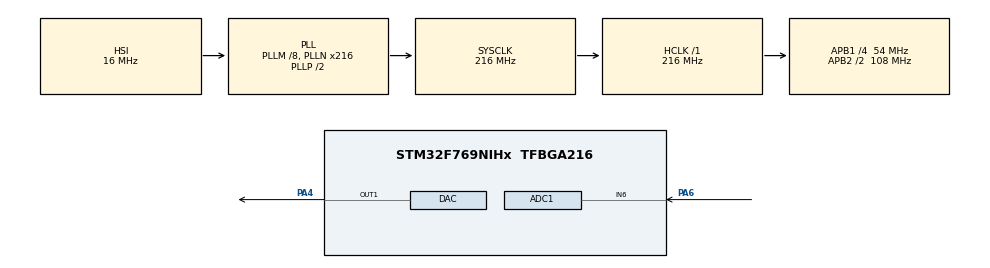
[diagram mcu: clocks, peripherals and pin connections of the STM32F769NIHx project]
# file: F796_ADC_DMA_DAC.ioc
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ADC1.Channel-3\#ChannelRegularConversion=ADC_CHANNEL_6
ADC1.ContinuousConvMode=DISABLE
ADC1.DMAContinuousRequests=ENABLE
ADC1.ExternalTrigConv=ADC_EXTERNALTRIGCONV_T6_TRGO
ADC1.InjNumberOfConversion=0
ADC1.NbrOfConversion=1
ADC1.NbrOfConversionFlag=1
ADC1.Rank-3\#ChannelRegularConversion=1
ADC1.Resolution=ADC_RESOLUTION_12B
ADC1.SamplingTime-3\#ChannelRegularConversion=ADC_SAMPLETIME_3CYCLES
ADC1.master=1
DAC.DAC_OutputBuffer=DAC_OUTPUTBUFFER_ENABLE
DAC.DAC_Trigger=DAC_TRIGGER_T6_TRGO
Dma.ADC1.1.Direction=DMA_PERIPH_TO_MEMORY
Dma.ADC1.1.FIFOMode=DMA_FIFOMODE_DISABLE
Dma.ADC1.1.Instance=DMA2_Stream0
Dma.ADC1.1.MemDataAlignment=DMA_MDATAALIGN_WORD
Dma.ADC1.1.MemInc=DMA_MINC_ENABLE
Dma.ADC1.1.Mode=DMA_CIRCULAR
Dma.ADC1.1.PeriphDataAlignment=DMA_PDATAALIGN_WORD
Dma.ADC1.1.PeriphInc=DMA_PINC_DISABLE
Dma.ADC1.1.Priority=DMA_PRIORITY_HIGH
Dma.DAC1.0.Direction=DMA_MEMORY_TO_PERIPH
Dma.DAC1.0.FIFOMode=DMA_FIFOMODE_DISABLE
Dma.DAC1.0.Instance=DMA1_Stream5
Dma.DAC1.0.MemDataAlignment=DMA_MDATAALIGN_WORD
Dma.DAC1.0.MemInc=DMA_MINC_ENABLE
Dma.DAC1.0.Mode=DMA_CIRCULAR
Dma.DAC1.0.PeriphDataAlignment=DMA_PDATAALIGN_WORD
Dma.DAC1.0.PeriphInc=DMA_PINC_DISABLE
Dma.DAC1.0.Priority=DMA_PRIORITY_HIGH
Dma.Request0=DAC1
Dma.Request1=ADC1
Mcu.Family=STM32F7
Mcu.Name=STM32F769NIHx
Mcu.Package=TFBGA216
NVIC.DMA1_Stream5_IRQn=true\:0\:0\:false\:false\:true\:false\:true
NVIC.DMA2_Stream0_IRQn=true\:0\:0\:false\:false\:true\:false\:true
NVIC.PriorityGroup=NVIC_PRIORITYGROUP_4
PA13.Mode=Serial_Wire
PA13.Signal=SYS_JTMS-SWDIO
PA14.Mode=Serial_Wire
PA14.Signal=SYS_JTCK-SWCLK
PA4.Signal=COMP_DAC1_group
PA6.Signal=ADCx_IN6
ProjectManager.HeapSize=0x200
ProjectManager.StackSize=0x400
ProjectManager.TargetToolchain=STM32CubeIDE
RCC.AHBFreq_Value=216000000
RCC.APB1CLKDivider=RCC_HCLK_DIV4
RCC.APB1Freq_Value=54000000
RCC.APB1TimFreq_Value=108000000
RCC.APB2CLKDivider=RCC_HCLK_DIV2
RCC.APB2Freq_Value=108000000
RCC.APB2TimFreq_Value=216000000
RCC.CortexFreq_Value=216000000
RCC.HCLKFreq_Value=216000000
RCC.HSE_VALUE=25000000
RCC.HSI_VALUE=16000000
RCC.LSE_VALUE=32768
RCC.PLLM=8
RCC.PLLN=216
RCC.PLLQ=4
RCC.PLLSAIQ=3
RCC.SYSCLKFreq_VALUE=216000000
RCC.SYSCLKSource=RCC_SYSCLKSOURCE_PLLCLK
RCC.USBFreq_Value=108000000
RCC.VCOOutputFreq_Value=432000000
SH.ADCx_IN6.0=ADC1_IN6,IN6
SH.COMP_DAC1_group.0=DAC_OUT1,DAC_OUT1
TIM6.Period=120
TIM6.TIM_MasterOutputTrigger=TIM_TRGO_UPDATE
VP_TIM6_VS_ClockSourceINT.Mode=Enable_Timer
board=STM32F769I-DISCO

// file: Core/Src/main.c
/* USER CODE BEGIN Header */
/**
  ******************************************************************************
  * @file           : main.c
  * @brief          : Main program body
  ******************************************************************************
  * @attention
  *
  * <h2><center>&copy; Copyright (c) 2021 STMicroelectronics.
  * All rights reserved.</center></h2>
  *
  * This software component is licensed by ST under BSD 3-Clause license,
  * the "License"; You may not use this file except in compliance with the
  * License. You may obtain a copy of the License at:
  *                        opensource.org/licenses/BSD-3-Clause
  *
  ******************************************************************************
  */
/* USER CODE END Header */

#include "main.h"

ADC_HandleTypeDef hadc1;
DMA_HandleTypeDef hdma_adc1;

DAC_HandleTypeDef hdac;
DMA_HandleTypeDef hdma_dac1;

TIM_HandleTypeDef htim6;

/* USER CODE BEGIN PV */
// adc and dac buffer

// number of samples user accesses per data block
#define DATASIZE 128

//  full buffer size
#define FULLBUFFERSIZE 256

uint32_t adc_val[FULLBUFFERSIZE];
uint32_t dac_val[FULLBUFFERSIZE];

// pointers to th half-buffers which should be processed
static volatile uint32_t* inbufPtr;
static volatile uint32_t* outbufPtr;

void processDSP();
/* USER CODE END PV */

void SystemClock_Config(void);
static void MX_GPIO_Init(void);
static void MX_DMA_Init(void);
static void MX_ADC1_Init(void);
static void MX_DAC_Init(void);
static void MX_TIM6_Init(void);

int main(void)
{

  /* MCU Configuration--------------------------------------------------------*/

  /* Reset of all peripherals, Initializes the Flash interface and the Systick. */
  HAL_Init();

  /* Configure the system clock */
  SystemClock_Config();

  /* Initialize all configured peripherals */
  MX_GPIO_Init();
  MX_DMA_Init();
  MX_ADC1_Init();
  MX_DAC_Init();
  MX_TIM6_Init();
  /* USER CODE BEGIN 2 */
  for( int i = 0; i < FULLBUFFERSIZE; i++) {
  	dac_val[i] = i * 12;
  }

  HAL_TIM_Base_Start(&htim6);
  HAL_ADC_Start_DMA(&hadc1, (uint32_t*) adc_val, FULLBUFFERSIZE);
  HAL_DAC_Start_DMA(&hdac, DAC_CHANNEL_1, (uint32_t*) adc_val, FULLBUFFERSIZE, DAC_ALIGN_12B_R);
  /* USER CODE END 2 */

  /* Infinite loop */
  while (1)
  {

    /* USER CODE BEGIN 3 */
	//processDSP();
  }
  /* USER CODE END 3 */
}

void SystemClock_Config(void)
{
  RCC_OscInitTypeDef RCC_OscInitStruct = {0};
  RCC_ClkInitTypeDef RCC_ClkInitStruct = {0};

  /** Configure the main internal regulator output voltage
  */
  __HAL_RCC_PWR_CLK_ENABLE();
  __HAL_PWR_VOLTAGESCALING_CONFIG(PWR_REGULATOR_VOLTAGE_SCALE1);
  /** Initializes the CPU, AHB and APB busses clocks
  */
  RCC_OscInitStruct.OscillatorType = RCC_OSCILLATORTYPE_HSI;
  RCC_OscInitStruct.HSIState = RCC_HSI_ON;
  RCC_OscInitStruct.HSICalibrationValue = RCC_HSICALIBRATION_DEFAULT;
  RCC_OscInitStruct.PLL.PLLState = RCC_PLL_ON;
  RCC_OscInitStruct.PLL.PLLSource = RCC_PLLSOURCE_HSI;
  RCC_OscInitStruct.PLL.PLLM = 8;
  RCC_OscInitStruct.PLL.PLLN = 216;
  RCC_OscInitStruct.PLL.PLLP = RCC_PLLP_DIV2;
  RCC_OscInitStruct.PLL.PLLQ = 4;
  if (HAL_RCC_OscConfig(&RCC_OscInitStruct) != HAL_OK)
  {
    Error_Handler();
  }
  /** Activate the Over-Drive mode
  */
  if (HAL_PWREx_EnableOverDrive() != HAL_OK)
  {
    Error_Handler();
  }
  /** Initializes the CPU, AHB and APB busses clocks
  */
  RCC_ClkInitStruct.ClockType = RCC_CLOCKTYPE_HCLK|RCC_CLOCKTYPE_SYSCLK
                              |RCC_CLOCKTYPE_PCLK1|RCC_CLOCKTYPE_PCLK2;
  RCC_ClkInitStruct.SYSCLKSource = RCC_SYSCLKSOURCE_PLLCLK;
  RCC_ClkInitStruct.AHBCLKDivider = RCC_SYSCLK_DIV1;
  RCC_ClkInitStruct.APB1CLKDivider = RCC_HCLK_DIV4;
  RCC_ClkInitStruct.APB2CLKDivider = RCC_HCLK_DIV2;

  if (HAL_RCC_ClockConfig(&RCC_ClkInitStruct, FLASH_LATENCY_7) != HAL_OK)
  {
    Error_Handler();
  }
}

static void MX_ADC1_Init(void)
{

  ADC_ChannelConfTypeDef sConfig = {0};

  /** Configure the global features of the ADC (Clock, Resolution, Data Alignment and number of conversion)
  */
  hadc1.Instance = ADC1;
  hadc1.Init.ClockPrescaler = ADC_CLOCK_SYNC_PCLK_DIV4;
  hadc1.Init.Resolution = ADC_RESOLUTION_12B;
  hadc1.Init.ScanConvMode = ADC_SCAN_DISABLE;
  hadc1.Init.ContinuousConvMode = DISABLE;
  hadc1.Init.DiscontinuousConvMode = DISABLE;
  hadc1.Init.ExternalTrigConvEdge = ADC_EXTERNALTRIGCONVEDGE_RISING;
  hadc1.Init.ExternalTrigConv = ADC_EXTERNALTRIGCONV_T6_TRGO;
  hadc1.Init.DataAlign = ADC_DATAALIGN_RIGHT;
  hadc1.Init.NbrOfConversion = 1;
  hadc1.Init.DMAContinuousRequests = ENABLE;
  hadc1.Init.EOCSelection = ADC_EOC_SINGLE_CONV;
  if (HAL_ADC_Init(&hadc1) != HAL_OK)
  {
    Error_Handler();
  }
  /** Configure for the selected ADC regular channel its corresponding rank in the sequencer and its sample time.
  */
  sConfig.Channel = ADC_CHANNEL_6;
  sConfig.Rank = ADC_REGULAR_RANK_1;
  sConfig.SamplingTime = ADC_SAMPLETIME_3CYCLES;
  if (HAL_ADC_ConfigChannel(&hadc1, &sConfig) != HAL_OK)
  {
    Error_Handler();
  }

}

static void MX_DAC_Init(void)
{

  DAC_ChannelConfTypeDef sConfig = {0};

  /** DAC Initialization
  */
  hdac.Instance = DAC;
  if (HAL_DAC_Init(&hdac) != HAL_OK)
  {
    Error_Handler();
  }
  /** DAC channel OUT1 config
  */
  sConfig.DAC_Trigger = DAC_TRIGGER_T6_TRGO;
  sConfig.DAC_OutputBuffer = DAC_OUTPUTBUFFER_ENABLE;
  if (HAL_DAC_ConfigChannel(&hdac, &sConfig, DAC_CHANNEL_1) != HAL_OK)
  {
    Error_Handler();
  }

}

static void MX_TIM6_Init(void)
{

  TIM_MasterConfigTypeDef sMasterConfig = {0};

  htim6.Instance = TIM6;
  htim6.Init.Prescaler = 0;
  htim6.Init.CounterMode = TIM_COUNTERMODE_UP;
  htim6.Init.Period = 120;
  htim6.Init.AutoReloadPreload = TIM_AUTORELOAD_PRELOAD_DISABLE;
  if (HAL_TIM_Base_Init(&htim6) != HAL_OK)
  {
    Error_Handler();
  }
  sMasterConfig.MasterOutputTrigger = TIM_TRGO_UPDATE;
  sMasterConfig.MasterSlaveMode = TIM_MASTERSLAVEMODE_DISABLE;
  if (HAL_TIMEx_MasterConfigSynchronization(&htim6, &sMasterConfig) != HAL_OK)
  {
    Error_Handler();
  }

}

static void MX_DMA_Init(void)
{

  /* DMA controller clock enable */
  __HAL_RCC_DMA1_CLK_ENABLE();
  __HAL_RCC_DMA2_CLK_ENABLE();

  /* DMA interrupt init */
  /* DMA1_Stream5_IRQn interrupt configuration */
  HAL_NVIC_SetPriority(DMA1_Stream5_IRQn, 0, 0);
  HAL_NVIC_EnableIRQ(DMA1_Stream5_IRQn);
  /* DMA2_Stream0_IRQn interrupt configuration */
  HAL_NVIC_SetPriority(DMA2_Stream0_IRQn, 0, 0);
  HAL_NVIC_EnableIRQ(DMA2_Stream0_IRQn);

}

static void MX_GPIO_Init(void)
{

  /* GPIO Ports Clock Enable */
  __HAL_RCC_GPIOA_CLK_ENABLE();

}

/* USER CODE BEGIN 4 */
void HAL_ADC_ConvHalfCpltCallback(ADC_HandleTypeDef* hadc) {
	// first half of the adc buffer is now full
	inbufPtr = &adc_val[0];
	outbufPtr = &dac_val[DATASIZE];
}

void HAL_ADC_ConvCpltCallback(ADC_HandleTypeDef* hadc) {
	inbufPtr = &adc_val[DATASIZE];
	outbufPtr = &dac_val[0];
}

// placeholder for DSP function block
void processDSP() {
	for( int n = 0; n < DATASIZE; n++) {
		outbufPtr[n] = inbufPtr[n];
	}
	//for( int i = 0; i < FULLBUFFERSIZE; i++) {
	//	dac_val[i] = i + 10;
	//}
}
/* USER CODE END 4 */

void Error_Handler(void)
{
}

/************************ (C) COPYRIGHT STMicroelectronics *****END OF FILE****/
